# ATSAM4S16C register map
Vendor: Atmel; File version: 0
CPU: CM4 r0p1, selectable endian, no MPU, no FPU, 0x4 interrupt priority bits, 0x0 interrupts
Registers are 32-bit, read-write, no defined reset value unless marked. A register's access mark holds for its fields unless they carry their own. Offsets are from the block's base; [hi:lo] are bit positions; {n}, {i} and the like mark numbered series.

## CRCCU — Cyclic Redundancy Check Calculation Unit
Base 0x40044000; register names take the prefix CRCCU_
0x00 DSCR reset 0x0 — CRCCU Descriptor Base Register
  [31:9] DSCR — Descriptor Base Address
0x08 DMA_EN wo — CRCCU DMA Enable Register
  [0] DMAEN — DMA Enable
0x0C DMA_DIS wo — CRCCU DMA Disable Register
  [0] DMADIS — DMA Disable
0x10 DMA_SR ro reset 0x0 — CRCCU DMA Status Register
  [0] DMASR — DMA Status
0x14 DMA_IER wo — CRCCU DMA Interrupt Enable Register
  [0] DMAIER — Interrupt Enable
0x18 DMA_IDR wo — CRCCU DMA Interrupt Disable Register
  [0] DMAIDR — Interrupt Disable
0x1C DMA_IMR ro reset 0x0 — CRCCU DMA Interrupt Mask Register
  [0] DMAIMR — Interrupt Mask
0x20 DMA_ISR ro reset 0x0 — CRCCU DMA Interrupt Status Register
  [0] DMAISR — Interrupt Status
0x34 CR wo — CRCCU Control Register
  [0] RESET — CRC Computation Reset
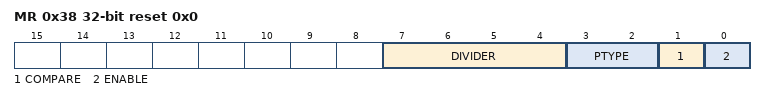
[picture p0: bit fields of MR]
0x38 MR reset 0x0 — CRCCU Mode Register
  [7:4] DIVIDER — Request Divider
  [3:2] PTYPE — Primitive Polynomial
    0=CCITT8023 (Polynom 0x04C11DB7); 1=CASTAGNOLI (Polynom 0x1EDC6F41); 2=CCITT16 (Polynom 0x1021)
  [1] COMPARE — CRC Compare
  [0] ENABLE — CRC Enable
0x3C SR ro reset 0xFFFFFFFF — CRCCU Status Register
  [31:0] CRC — Cyclic Redundancy Check Value
0x40 IER wo — CRCCU Interrupt Enable Register
  [0] ERRIER — CRC Error Interrupt Enable
0x44 IDR wo — CRCCU Interrupt Disable Register
  [0] ERRIDR — CRC Error Interrupt Disable
0x48 IMR ro reset 0x0 — CRCCU Interrupt Mask Register
  [0] ERRIMR — CRC Error Interrupt Mask
0x4C ISR ro reset 0x0 — CRCCU Interrupt Status Register
  [0] ERRISR — CRC Error Interrupt Status

## SMC — Static Memory Controller
Base 0x400E0000; register names take the prefix SMC_
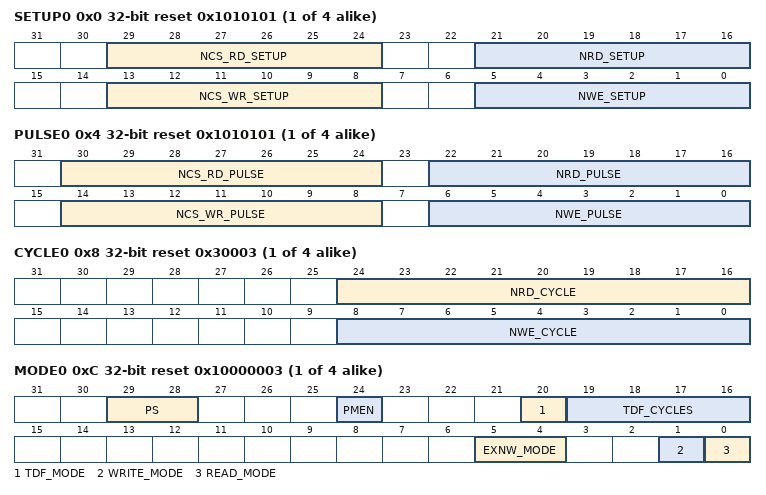
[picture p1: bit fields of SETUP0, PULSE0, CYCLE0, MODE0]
{0x0+0x10*i} SETUP{i} reset 0x1010101 (i=0..3) — SMC Setup Register (CS_number = {i})
  [29:24] NCS_RD_SETUP — NCS Setup Length in READ Access
  [21:16] NRD_SETUP — NRD Setup Length
  [13:8] NCS_WR_SETUP — NCS Setup Length in WRITE Access
  [5:0] NWE_SETUP — NWE Setup Length
{0x4+0x10*i} PULSE{i} reset 0x1010101 (i=0..3) — SMC Pulse Register (CS_number = {i})
  [30:24] NCS_RD_PULSE — NCS Pulse Length in READ Access
  [22:16] NRD_PULSE — NRD Pulse Length
  [14:8] NCS_WR_PULSE — NCS Pulse Length in WRITE Access
  [6:0] NWE_PULSE — NWE Pulse Length
{0x8+0x10*i} CYCLE{i} reset 0x30003 (i=0..3) — SMC Cycle Register (CS_number = {i})
  [24:16] NRD_CYCLE — Total Read Cycle Length
  [8:0] NWE_CYCLE — Total Write Cycle Length
{0xC+0x10*i} MODE{i} reset 0x10000003 (i=0..3) — SMC MODE Register (CS_number = {i})
  [29:28] PS — Page Size
    0=4_BYTE (4-byte page); 1=8_BYTE (8-byte page); 2=16_BYTE (16-byte page); 3=32_BYTE (32-byte page)
  [24] PMEN — Page Mode Enabled
  [20] TDF_MODE — TDF Optimization
  [19:16] TDF_CYCLES — Data Float Time
  [5:4] EXNW_MODE — NWAIT Mode
    0=DISABLED; 2=FROZEN (Frozen Mode); 3=READY (Ready Mode)
  [1] WRITE_MODE
  [0] READ_MODE
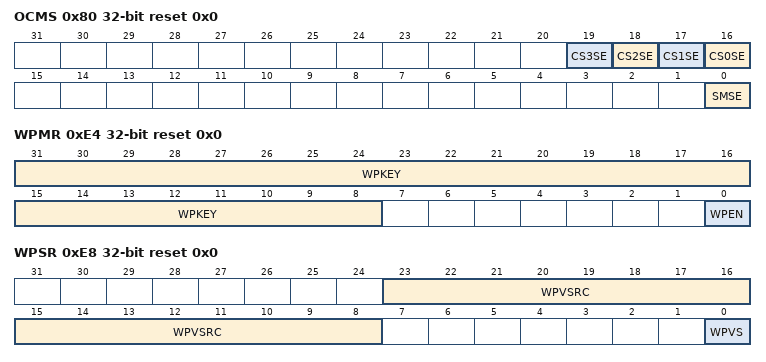
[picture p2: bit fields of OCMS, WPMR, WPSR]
0x80 OCMS reset 0x0 — SMC OCMS MODE Register
  [n+16] CS{n}SE (n=0..3) — Chip Select (x = 0 to 3) Scrambling Enable
  [0] SMSE — Static Memory Controller Scrambling Enable
0x84 KEY1 wo reset 0x0 — SMC OCMS KEY1 Register
  [31:0] KEY1 — Off Chip Memory Scrambling (OCMS) Key Part 1
0x88 KEY2 wo reset 0x0 — SMC OCMS KEY2 Register
  [31:0] KEY2 — Off Chip Memory Scrambling (OCMS) Key Part 2
0xE4 WPMR reset 0x0 — SMC Write Protection Mode Register
  [31:8] WPKEY — Write Protection Key
    0x534D43=PASSWD (Writing any other value in this field aborts the write operation of the WPEN bit. Always reads as 0.)
  [0] WPEN — Write Protect Enable
0xE8 WPSR ro reset 0x0 — SMC Write Protection Status Register
  [23:8] WPVSRC — Write Protection Violation Source
  [0] WPVS — Write Protection Violation Status
